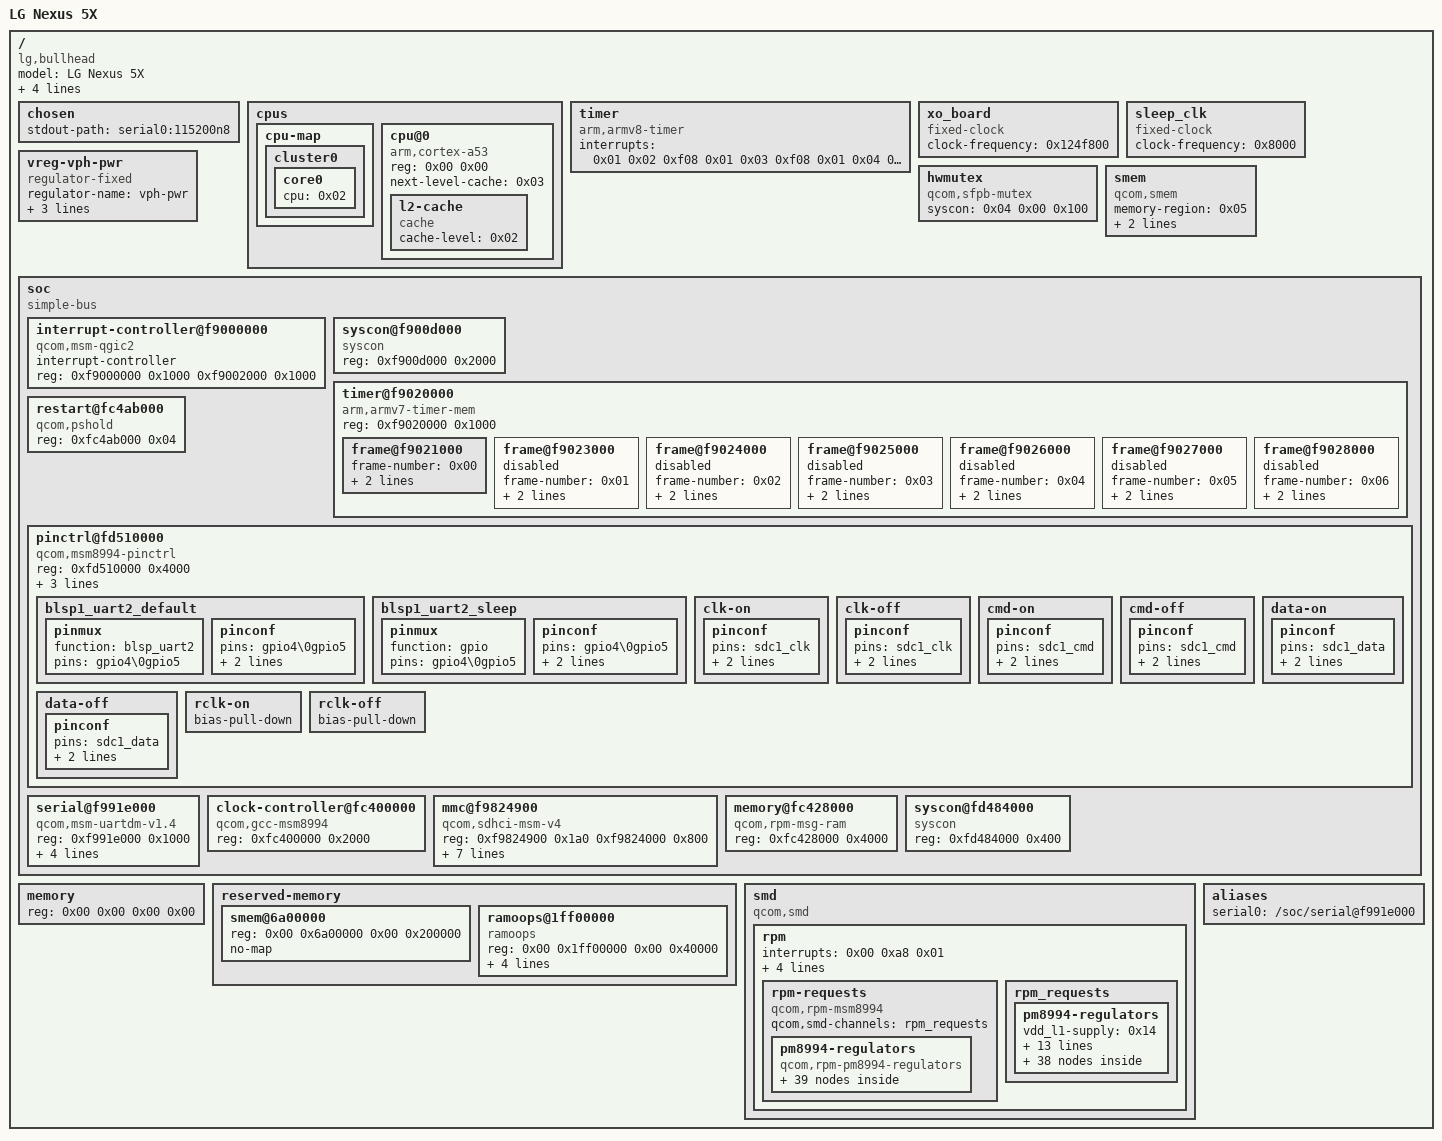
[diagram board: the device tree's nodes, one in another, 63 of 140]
/dts-v1/;

/ {
	model = "LG Nexus 5X";
	compatible = "lg,bullhead\0qcom,msm8992";
	qcom,msm-id = <0xfb 0x00 0xfc 0x00>;
	interrupt-parent = <0x01>;
	#address-cells = <0x02>;
	#size-cells = <0x02>;
	qcom,board-id = <0xb64 0x00>;
	qcom,pmic-id = <0x10009 0x1000a 0x00 0x00>;

	chosen {
		stdout-path = "serial0:115200n8";
	};

	cpus {
		#address-cells = <0x02>;
		#size-cells = <0x00>;

		cpu-map {

			cluster0 {

				core0 {
					cpu = <0x02>;
				};
			};
		};

		cpu@0 {
			device_type = "cpu";
			compatible = "arm,cortex-a53\0arm,armv8";
			reg = <0x00 0x00>;
			next-level-cache = <0x03>;
			phandle = <0x02>;

			l2-cache {
				compatible = "cache";
				cache-level = <0x02>;
				phandle = <0x03>;
			};
		};
	};

	timer {
		compatible = "arm,armv8-timer";
		interrupts = <0x01 0x02 0xf08 0x01 0x03 0xf08 0x01 0x04 0xf08 0x01 0x01 0xf08>;
	};

	xo_board {
		compatible = "fixed-clock";
		#clock-cells = <0x00>;
		clock-frequency = <0x124f800>;
	};

	sleep_clk {
		compatible = "fixed-clock";
		#clock-cells = <0x00>;
		clock-frequency = <0x8000>;
	};

	vreg-vph-pwr {
		compatible = "regulator-fixed";
		status = "okay";
		regulator-name = "vph-pwr";
		regulator-min-microvolt = <0x36ee80>;
		regulator-max-microvolt = <0x36ee80>;
		regulator-always-on;
		phandle = <0x17>;
	};

	hwmutex {
		compatible = "qcom,sfpb-mutex";
		syscon = <0x04 0x00 0x100>;
		#hwlock-cells = <0x01>;
		phandle = <0x07>;
	};

	smem {
		compatible = "qcom,smem";
		memory-region = <0x05>;
		qcom,rpm-msg-ram = <0x06>;
		hwlocks = <0x07 0x03>;
	};

	soc {
		#address-cells = <0x01>;
		#size-cells = <0x01>;
		ranges = <0x00 0x00 0x00 0xffffffff>;
		compatible = "simple-bus";

		interrupt-controller@f9000000 {
			compatible = "qcom,msm-qgic2";
			interrupt-controller;
			#interrupt-cells = <0x03>;
			reg = <0xf9000000 0x1000 0xf9002000 0x1000>;
			phandle = <0x01>;
		};

		syscon@f900d000 {
			compatible = "syscon";
			reg = <0xf900d000 0x2000>;
			phandle = <0x13>;
		};

		timer@f9020000 {
			#address-cells = <0x01>;
			#size-cells = <0x01>;
			ranges;
			compatible = "arm,armv7-timer-mem";
			reg = <0xf9020000 0x1000>;

			frame@f9021000 {
				frame-number = <0x00>;
				interrupts = <0x00 0x09 0x04 0x00 0x08 0x04>;
				reg = <0xf9021000 0x1000 0xf9022000 0x1000>;
			};

			frame@f9023000 {
				frame-number = <0x01>;
				interrupts = <0x00 0x0a 0x04>;
				reg = <0xf9023000 0x1000>;
				status = "disabled";
			};

			frame@f9024000 {
				frame-number = <0x02>;
				interrupts = <0x00 0x0b 0x04>;
				reg = <0xf9024000 0x1000>;
				status = "disabled";
			};

			frame@f9025000 {
				frame-number = <0x03>;
				interrupts = <0x00 0x0c 0x04>;
				reg = <0xf9025000 0x1000>;
				status = "disabled";
			};

			frame@f9026000 {
				frame-number = <0x04>;
				interrupts = <0x00 0x0d 0x04>;
				reg = <0xf9026000 0x1000>;
				status = "disabled";
			};

			frame@f9027000 {
				frame-number = <0x05>;
				interrupts = <0x00 0x0e 0x04>;
				reg = <0xf9027000 0x1000>;
				status = "disabled";
			};

			frame@f9028000 {
				frame-number = <0x06>;
				interrupts = <0x00 0x0f 0x04>;
				reg = <0xf9028000 0x1000>;
				status = "disabled";
			};
		};

		restart@fc4ab000 {
			compatible = "qcom,pshold";
			reg = <0xfc4ab000 0x04>;
		};

		pinctrl@fd510000 {
			compatible = "qcom,msm8994-pinctrl";
			reg = <0xfd510000 0x4000>;
			interrupts = <0x00 0xd0 0x04>;
			gpio-controller;
			#gpio-cells = <0x02>;
			interrupt-controller;
			#interrupt-cells = <0x02>;

			blsp1_uart2_default {
				phandle = <0x09>;

				pinmux {
					function = "blsp_uart2";
					pins = "gpio4\0gpio5";
				};

				pinconf {
					pins = "gpio4\0gpio5";
					drive-strength = <0x10>;
					bias-disable;
				};
			};

			blsp1_uart2_sleep {
				phandle = <0x0a>;

				pinmux {
					function = "gpio";
					pins = "gpio4\0gpio5";
				};

				pinconf {
					pins = "gpio4\0gpio5";
					drive-strength = <0x02>;
					bias-pull-down;
				};
			};

			clk-on {
				phandle = <0x0b>;

				pinconf {
					pins = "sdc1_clk";
					bias-disable = <0x00>;
					drive-strength = <0x10>;
				};
			};

			clk-off {
				phandle = <0x0f>;

				pinconf {
					pins = "sdc1_clk";
					bias-disable = <0x00>;
					drive-strength = <0x02>;
				};
			};

			cmd-on {
				phandle = <0x0c>;

				pinconf {
					pins = "sdc1_cmd";
					bias-pull-up;
					drive-strength = <0x08>;
				};
			};

			cmd-off {
				phandle = <0x10>;

				pinconf {
					pins = "sdc1_cmd";
					bias-pull-up = <0x03>;
					drive-strength = <0x02>;
				};
			};

			data-on {
				phandle = <0x0d>;

				pinconf {
					pins = "sdc1_data";
					bias-pull-up;
					drive-strength = <0x08>;
				};
			};

			data-off {
				phandle = <0x11>;

				pinconf {
					pins = "sdc1_data";
					bias-pull-up;
					drive-strength = <0x02>;
				};
			};

			rclk-on {
				bias-pull-down;
				phandle = <0x0e>;
			};

			rclk-off {
				bias-pull-down;
				phandle = <0x12>;
			};
		};

		serial@f991e000 {
			compatible = "qcom,msm-uartdm-v1.4\0qcom,msm-uartdm";
			reg = <0xf991e000 0x1000>;
			interrupts = <0x00 0x6c 0x08>;
			status = "okay";
			clock-names = "core\0iface";
			clocks = <0x08 0x48 0x08 0x3a>;
			pinctrl-names = "default\0sleep";
			pinctrl-0 = <0x09>;
			pinctrl-1 = <0x0a>;
		};

		clock-controller@fc400000 {
			compatible = "qcom,gcc-msm8994";
			#clock-cells = <0x01>;
			#reset-cells = <0x01>;
			#power-domain-cells = <0x01>;
			reg = <0xfc400000 0x2000>;
			phandle = <0x08>;
		};

		mmc@f9824900 {
			compatible = "qcom,sdhci-msm-v4";
			reg = <0xf9824900 0x1a0 0xf9824000 0x800>;
			reg-names = "hc_mem\0core_mem";
			interrupts = <0x00 0x7b 0x00 0x00 0x8a 0x00>;
			interrupt-names = "hc_irq\0pwr_irq";
			clocks = <0x08 0x68 0x08 0x76>;
			clock-names = "core\0iface";
			pinctrl-names = "default\0sleep";
			pinctrl-0 = <0x0b 0x0c 0x0d 0x0e>;
			pinctrl-1 = <0x0f 0x10 0x11 0x12>;
			regulator-always-on;
			bus-width = <0x08>;
			mmc-hs400-1_8v;
			status = "okay";
		};

		memory@fc428000 {
			compatible = "qcom,rpm-msg-ram";
			reg = <0xfc428000 0x4000>;
			phandle = <0x06>;
		};

		syscon@fd484000 {
			#address-cells = <0x01>;
			#size-cells = <0x01>;
			compatible = "syscon";
			reg = <0xfd484000 0x400>;
			phandle = <0x04>;
		};
	};

	memory {
		device_type = "memory";
		reg = <0x00 0x00 0x00 0x00>;
	};

	reserved-memory {
		#address-cells = <0x02>;
		#size-cells = <0x02>;
		ranges;

		smem@6a00000 {
			reg = <0x00 0x6a00000 0x00 0x200000>;
			no-map;
			phandle = <0x05>;
		};

		ramoops@1ff00000 {
			compatible = "ramoops";
			reg = <0x00 0x1ff00000 0x00 0x40000>;
			console-size = <0x10000>;
			record-size = <0x10000>;
			ftrace-size = <0x10000>;
			pmsg-size = <0x20000>;
		};
	};

	smd {
		compatible = "qcom,smd";

		rpm {
			interrupts = <0x00 0xa8 0x01>;
			qcom,ipc = <0x13 0x08 0x00>;
			qcom,smd-edge = <0x0f>;
			qcom,local-pid = <0x00>;
			qcom,remote-pid = <0x06>;

			rpm-requests {
				compatible = "qcom,rpm-msm8994";
				qcom,smd-channels = "rpm_requests";

				pm8994-regulators {
					compatible = "qcom,rpm-pm8994-regulators";

					s1 {
						phandle = <0x14>;
					};

					s2 {
					};

					s3 {
						phandle = <0x15>;
					};

					s4 {
						phandle = <0x18>;
					};

					s5 {
						phandle = <0x16>;
					};

					s6 {
					};

					s7 {
					};

					l1 {
					};

					l2 {
					};

					l3 {
					};

					l4 {
					};

					l6 {
					};

					l8 {
					};

					l9 {
					};

					l10 {
					};

					l11 {
					};

					l12 {
						phandle = <0x19>;
					};

					l13 {
					};

					l14 {
						phandle = <0x1a>;
					};

					l15 {
					};

					l16 {
					};

					l17 {
					};

					l18 {
					};

					l19 {
					};

					l20 {
					};

					l21 {
					};

					l22 {
					};

					l23 {
					};

					l24 {
					};

					l25 {
					};

					l26 {
					};

					l27 {
					};

					l28 {
						phandle = <0x1b>;
					};

					l29 {
					};

					l30 {
					};

					l31 {
					};

					l32 {
					};

					lvs1 {
					};

					lvs2 {
					};
				};
			};

			rpm_requests {

				pm8994-regulators {
					vdd_l1-supply = <0x14>;
					vdd_l2_26_28-supply = <0x15>;
					vdd_l3_11-supply = <0x15>;
					vdd_l4_27_31-supply = <0x15>;
					vdd_l5_7-supply = <0x15>;
					vdd_l6_12_32-supply = <0x16>;
					vdd_l8_16_30-supply = <0x17>;
					vdd_l9_10_18_22-supply = <0x17>;
					vdd_l13_19_23_24-supply = <0x17>;
					vdd_l14_15-supply = <0x16>;
					vdd_l17_29-supply = <0x17>;
					vdd_l20_21-supply = <0x17>;
					vdd_l25-supply = <0x16>;
					vdd_lvs1_2 = <0x18>;

					s1 {
						regulator-min-microvolt = "\0\f5";
						regulator-max-microvolt = "\0\f5";
					};

					s2 {
					};

					s3 {
						regulator-min-microvolt = <0x13d620>;
						regulator-max-microvolt = <0x13d620>;
					};

					s4 {
						regulator-min-microvolt = <0x1b7740>;
						regulator-max-microvolt = <0x1b7740>;
						regulator-allow-set-load;
						regulator-system-load = <0x4f588>;
					};

					s5 {
						regulator-min-microvolt = <0x20ce70>;
						regulator-max-microvolt = <0x20ce70>;
					};

					s7 {
						regulator-min-microvolt = <0xf4240>;
						regulator-max-microvolt = <0xf4240>;
					};

					l1 {
						regulator-min-microvolt = <0xf4240>;
						regulator-max-microvolt = <0xf4240>;
					};

					l2 {
						regulator-min-microvolt = <0x1312d0>;
						regulator-max-microvolt = <0x1312d0>;
					};

					l3 {
						regulator-min-microvolt = <0x124f80>;
						regulator-max-microvolt = <0x124f80>;
					};

					l4 {
						regulator-min-microvolt = <0x12b128>;
						regulator-max-microvolt = <0x12b128>;
					};

					l5 {
					};

					l6 {
						regulator-min-microvolt = <0x1b7740>;
						regulator-max-microvolt = <0x1b7740>;
					};

					l7 {
					};

					l8 {
						regulator-min-microvolt = <0x1b7740>;
						regulator-max-microvolt = <0x1b7740>;
					};

					l9 {
						regulator-min-microvolt = <0x1b7740>;
						regulator-max-microvolt = <0x1b7740>;
					};

					l10 {
						regulator-min-microvolt = <0x1b7740>;
						regulator-max-microvolt = <0x1b7740>;
						qcom,init-voltage = <0x1b7740>;
					};

					l11 {
						regulator-min-microvolt = <0x124f80>;
						regulator-max-microvolt = <0x124f80>;
						qcom,init-voltage = <0x124f80>;
					};

					l12 {
						regulator-min-microvolt = <0x1b7740>;
						regulator-max-microvolt = <0x1b7740>;
						qcom,init-voltage = <0x1b7740>;
						proxy-supply = <0x19>;
						qcom,proxy-consumer-enable;
						qcom,proxy-consumer-current = <0x2710>;
						status = "okay";
					};

					l13 {
						regulator-min-microvolt = <0x1b7740>;
						regulator-max-microvolt = <0x2d0370>;
						qcom,init-voltage = <0x2d0370>;
						status = "okay";
					};

					l14 {
						regulator-min-microvolt = <0x124f80>;
						regulator-max-microvolt = <0x124f80>;
						qcom,init-voltage = <0x124f80>;
						proxy-supply = <0x1a>;
						qcom,proxy-consumer-enable;
						qcom,proxy-consumer-current = <0x2710>;
						status = "okay";
					};

					l15 {
						regulator-min-microvolt = <0x1b7740>;
						regulator-max-microvolt = <0x1b7740>;
						qcom,init-voltage = <0x1b7740>;
						status = "okay";
					};

					l16 {
						regulator-min-microvolt = <0x2932e0>;
						regulator-max-microvolt = <0x2932e0>;
						qcom,init-voltage = <0x2932e0>;
						status = "okay";
					};

					l17 {
						regulator-min-microvolt = <0x2932e0>;
						regulator-max-microvolt = <0x2932e0>;
						qcom,init-voltage = <0x2932e0>;
						status = "okay";
					};

					l18 {
						regulator-min-microvolt = <0x2dc6c0>;
						regulator-max-microvolt = <0x2dc6c0>;
						regulator-always-on;
						qcom,init-voltage = <0x2dc6c0>;
						qcom,init-ldo-mode = <0x01>;
					};

					l19 {
						regulator-min-microvolt = <0x1b7740>;
						regulator-max-microvolt = <0x1b7740>;
						qcom,init-voltage = <0x1b7740>;
						status = "okay";
					};

					l20 {
						regulator-min-microvolt = <0x2d0370>;
						regulator-max-microvolt = <0x2d0370>;
						regulator-always-on;
						regulator-boot-on;
						regulator-allow-set-load;
						regulator-system-load = <0x8b290>;
					};

					l21 {
						regulator-min-microvolt = <0x1b7740>;
						regulator-max-microvolt = <0x1b7740>;
						regulator-always-on;
						qcom,init-voltage = <0x1b7740>;
					};

					l22 {
						regulator-min-microvolt = <0x2f4d60>;
						regulator-max-microvolt = <0x2f4d60>;
						qcom,init-voltage = <0x2f4d60>;
					};

					l23 {
						regulator-min-microvolt = <0x2ab980>;
						regulator-max-microvolt = <0x2ab980>;
						qcom,init-voltage = <0x2ab980>;
					};

					l24 {
						regulator-min-microvolt = <0x2eebb8>;
						regulator-max-microvolt = <0x3010b0>;
						qcom,init-voltage = <0x2eebb8>;
					};

					l25 {
						regulator-min-microvolt = <0x1b7740>;
						regulator-max-microvolt = <0x1b7740>;
						qcom,init-voltage = <0x1b7740>;
					};

					l26 {
					};

					l27 {
						regulator-min-microvolt = <0x100590>;
						regulator-max-microvolt = <0x100590>;
						qcom,init-voltage = <0x100590>;
					};

					l28 {
						regulator-min-microvolt = <0xf4240>;
						regulator-max-microvolt = <0xf4240>;
						qcom,init-voltage = <0xf4240>;
						proxy-supply = <0x1b>;
						qcom,proxy-consumer-enable;
						qcom,proxy-consumer-current = <0x2710>;
					};

					l29 {
					};

					l30 {
					};

					l31 {
						regulator-min-microvolt = <0x1343a4>;
						regulator-max-microvolt = <0x1343a4>;
						qcom,init-voltage = <0x1343a4>;
					};

					l32 {
					};
				};
			};
		};
	};

	aliases {
		serial0 = "/soc/serial@f991e000";
	};
};
